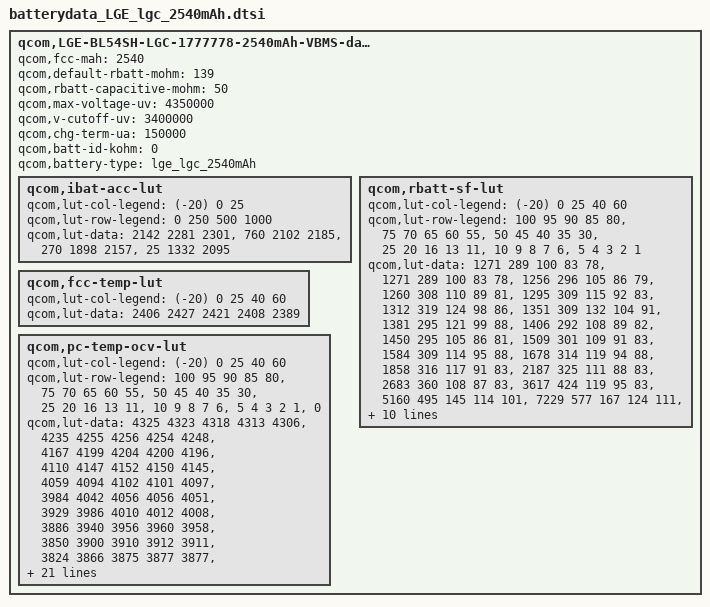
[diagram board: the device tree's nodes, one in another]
/* Copyright (c) 2014, The Linux Foundation. All rights reserved.
 *
 * This program is free software; you can redistribute it and/or modify
 * it under the terms of the GNU General Public License version 2 and
 * only version 2 as published by the Free Software Foundation.
 *
 * This program is distributed in the hope that it will be useful,
 * but WITHOUT ANY WARRANTY; without even the implied warranty of
 * MERCHANTABILITY or FITNESS FOR A PARTICULAR PURPOSE.  See the
 * GNU General Public License for more details.
 */
 qcom,LGE-BL54SH-LGC-1777778-2540mAh-VBMS-data {
	qcom,fcc-mah = <2540>;
	qcom,default-rbatt-mohm = <139>;
	qcom,rbatt-capacitive-mohm = <50>;
	qcom,max-voltage-uv = <4350000>;
	qcom,v-cutoff-uv = <3400000>;
	qcom,chg-term-ua = <150000>;
	qcom,batt-id-kohm = <0>;
	qcom,battery-type = "lge_lgc_2540mAh";

	qcom,ibat-acc-lut {
		qcom,lut-col-legend = <(-20) 0 25>;
		qcom,lut-row-legend = <0 250 500 1000>;
		qcom,lut-data = <2142 2281 2301>,
				<760 2102 2185>,
				<270 1898 2157>,
				<25 1332 2095>;
	};

	qcom,rbatt-sf-lut {
		qcom,lut-col-legend = <(-20) 0 25 40 60>;
		qcom,lut-row-legend = <100 95 90 85 80>,
				<75 70 65 60 55>,
				<50 45 40 35 30>,
				<25 20 16 13 11>,
				<10 9 8 7 6>,
				<5 4 3 2 1>;
		qcom,lut-data = <1271 289 100 83 78>,
				<1271 289 100 83 78>,
				<1256 296 105 86 79>,
				<1260 308 110 89 81>,
				<1295 309 115 92 83>,
				<1312 319 124 98 86>,
				<1351 309 132 104 91>,
				<1381 295 121 99 88>,
				<1406 292 108 89 82>,
				<1450 295 105 86 81>,
				<1509 301 109 91 83>,
				<1584 309 114 95 88>,
				<1678 314 119 94 88>,
				<1858 316 117 91 83>,
				<2187 325 111 88 83>,
				<2683 360 108 87 83>,
				<3617 424 119 95 83>,
				<5160 495 145 114 101>,
				<7229 577 167 124 111>,
				<9121 650 184 132 115>,
				<10181 695 196 138 119>,
				<11479 740 207 145 125>,
				<13076 798 226 153 131>,
				<14535 852 247 164 137>,
				<16312 799 263 177 144>,
				<18786 882 283 192 154>,
				<22640 1142 314 210 166>,
				<27175 1633 363 233 183>,
				<32980 2408 454 278 212>,
				<39655 3974 622 373 283>;
	};

	qcom,fcc-temp-lut {
		qcom,lut-col-legend = <(-20) 0 25 40 60>;
		qcom,lut-data = <2406 2427 2421 2408 2389>;
	};

	qcom,pc-temp-ocv-lut {
		qcom,lut-col-legend = <(-20) 0 25 40 60>;
		qcom,lut-row-legend = <100 95 90 85 80>,
				<75 70 65 60 55>,
				<50 45 40 35 30>,
				<25 20 16 13 11>,
				<10 9 8 7 6>,
				<5 4 3 2 1>,
				<0>;
		qcom,lut-data = <4325 4323 4318 4313 4306>,
				<4235 4255 4256 4254 4248>,
				<4167 4199 4204 4200 4196>,
				<4110 4147 4152 4150 4145>,
				<4059 4094 4102 4101 4097>,
				<3984 4042 4056 4056 4051>,
				<3929 3986 4010 4012 4008>,
				<3886 3940 3956 3960 3958>,
				<3850 3900 3910 3912 3911>,
				<3824 3866 3875 3877 3877>,
				<3801 3837 3848 3850 3850>,
				<3780 3810 3824 3825 3825>,
				<3758 3786 3802 3800 3797>,
				<3734 3760 3776 3770 3761>,
				<3707 3736 3738 3734 3725>,
				<3670 3714 3702 3694 3682>,
				<3608 3686 3679 3674 3666>,
				<3518 3650 3650 3646 3632>,
				<3446 3582 3599 3595 3583>,
				<3395 3532 3556 3554 3542>,
				<3370 3504 3530 3528 3518>,
				<3348 3478 3504 3501 3494>,
				<3327 3448 3477 3474 3468>,
				<3306 3418 3450 3450 3442>,
				<3282 3388 3422 3422 3416>,
				<3260 3355 3390 3392 3386>,
				<3240 3320 3354 3354 3350>,
				<3213 3278 3307 3306 3301>,
				<3175 3224 3245 3243 3233>,
				<3103 3150 3156 3151 3141>,
				<3000 3000 3000 3000 3000>;
	};
};
